# ioam3358 register map
Registers are 32-bit, access not given, no defined reset value unless marked. A register's access mark holds for its fields unless they carry their own. Addresses are absolute; registers are grouped by the start of their names; [hi:lo] are bit positions; {n}, {i} and the like mark numbered series.

## MMCHS2
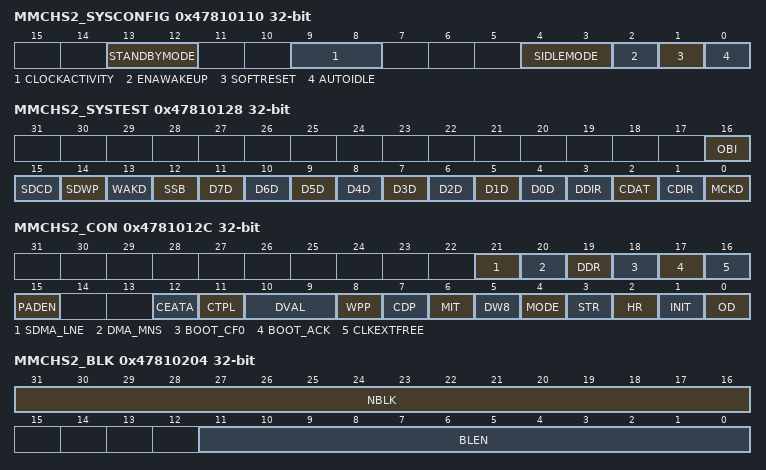
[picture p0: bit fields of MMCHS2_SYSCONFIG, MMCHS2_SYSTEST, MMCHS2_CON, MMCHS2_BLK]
0x47810110 MMCHS2_SYSCONFIG
  [13:12] STANDBYMODE, [9:8] CLOCKACTIVITY, [4:3] SIDLEMODE, [2] ENAWAKEUP, [1] SOFTRESET, [0] AUTOIDLE
0x47810114 MMCHS2_SYSSTATUS
  [0] RESETDONE
0x47810124 MMCHS2_CSRE
0x47810128 MMCHS2_SYSTEST
  [16] OBI, [15] SDCD, [14] SDWP, [13] WAKD, [12] SSB, [n+4] D{n}D (n=0..7), [3] DDIR, [2] CDAT, [1] CDIR, [0] MCKD
0x4781012C MMCHS2_CON
  [21] SDMA_LNE, [20] DMA_MNS, [19] DDR, [18] BOOT_CF0, [17] BOOT_ACK, [16] CLKEXTFREE, [15] PADEN, [12] CEATA, [11] CTPL, [10:9] DVAL, [8] WPP, [7] CDP, [6] MIT, [5] DW8, [4] MODE, [3] STR, [2] HR, [1] INIT, [0] OD
0x47810130 MMCHS2_PWCNT
  [15:0] PWRCNT
0x47810200 MMCHS2_SDMASA
0x47810204 MMCHS2_BLK
  [31:16] NBLK, [11:0] BLEN
0x47810208 MMCHS2_ARG
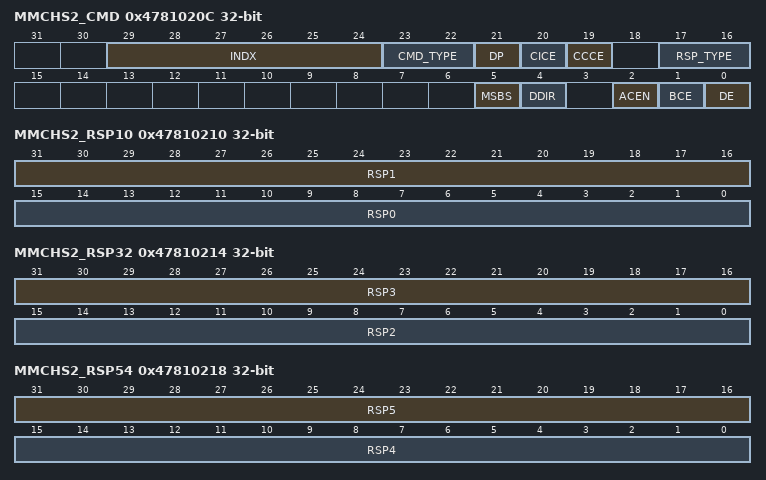
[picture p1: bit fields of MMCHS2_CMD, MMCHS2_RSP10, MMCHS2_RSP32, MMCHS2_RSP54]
0x4781020C MMCHS2_CMD
  [29:24] INDX, [23:22] CMD_TYPE, [21] DP, [20] CICE, [19] CCCE, [17:16] RSP_TYPE, [5] MSBS, [4] DDIR, [2] ACEN, [1] BCE, [0] DE
0x47810210 MMCHS2_RSP10
  [31:16] RSP1, [15:0] RSP0
0x47810214 MMCHS2_RSP32
  [31:16] RSP3, [15:0] RSP2
0x47810218 MMCHS2_RSP54
  [31:16] RSP5, [15:0] RSP4
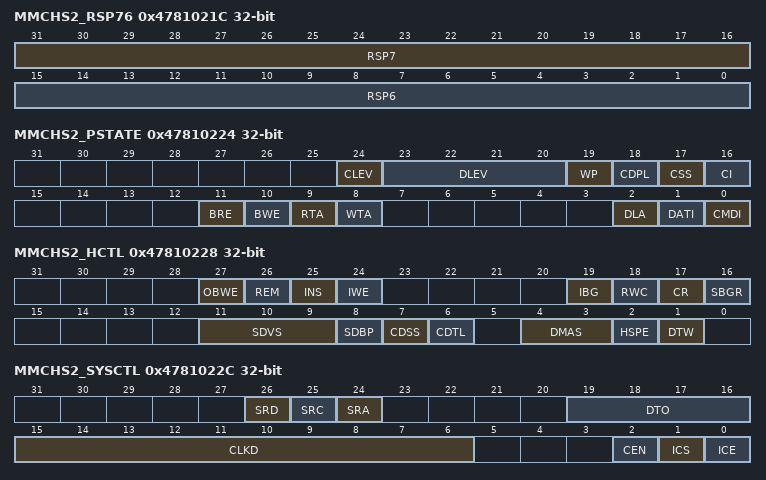
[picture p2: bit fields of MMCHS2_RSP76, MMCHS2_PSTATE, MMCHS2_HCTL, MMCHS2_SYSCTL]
0x4781021C MMCHS2_RSP76
  [31:16] RSP7, [15:0] RSP6
0x47810220 MMCHS2_DATA
0x47810224 MMCHS2_PSTATE
  [24] CLEV, [23:20] DLEV, [19] WP, [18] CDPL, [17] CSS, [16] CI, [11] BRE, [10] BWE, [9] RTA, [8] WTA, [2] DLA, [1] DATI, [0] CMDI
0x47810228 MMCHS2_HCTL
  [27] OBWE, [26] REM, [25] INS, [24] IWE, [19] IBG, [18] RWC, [17] CR, [16] SBGR, [11:9] SDVS, [8] SDBP, [7] CDSS, [6] CDTL, [4:3] DMAS, [2] HSPE, [1] DTW
0x4781022C MMCHS2_SYSCTL
  [26] SRD, [25] SRC, [24] SRA, [19:16] DTO, [15:6] CLKD, [2] CEN, [1] ICS, [0] ICE
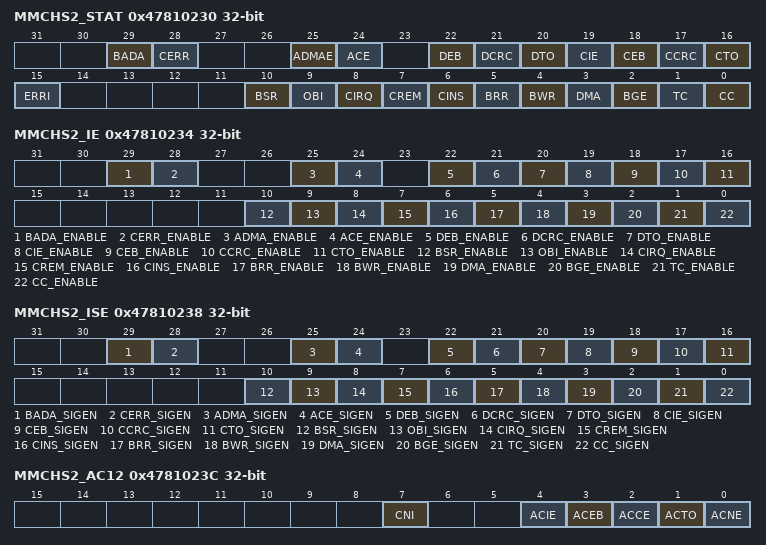
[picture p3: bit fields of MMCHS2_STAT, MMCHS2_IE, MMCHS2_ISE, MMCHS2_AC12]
0x47810230 MMCHS2_STAT
  [29] BADA, [28] CERR, [25] ADMAE, [24] ACE, [22] DEB, [21] DCRC, [20] DTO, [19] CIE, [18] CEB, [17] CCRC, [16] CTO, [15] ERRI, [10] BSR, [9] OBI, [8] CIRQ, [7] CREM, [6] CINS, [5] BRR, [4] BWR, [3] DMA, [2] BGE, [1] TC, [0] CC
0x47810234 MMCHS2_IE
  [29] BADA_ENABLE, [28] CERR_ENABLE, [25] ADMA_ENABLE, [24] ACE_ENABLE, [22] DEB_ENABLE, [21] DCRC_ENABLE, [20] DTO_ENABLE, [19] CIE_ENABLE, [18] CEB_ENABLE, [17] CCRC_ENABLE, [16] CTO_ENABLE, [10] BSR_ENABLE, [9] OBI_ENABLE, [8] CIRQ_ENABLE, [7] CREM_ENABLE, [6] CINS_ENABLE, [5] BRR_ENABLE, [4] BWR_ENABLE, [3] DMA_ENABLE, [2] BGE_ENABLE, [1] TC_ENABLE, [0] CC_ENABLE
0x47810238 MMCHS2_ISE
  [29] BADA_SIGEN, [28] CERR_SIGEN, [25] ADMA_SIGEN, [24] ACE_SIGEN, [22] DEB_SIGEN, [21] DCRC_SIGEN, [20] DTO_SIGEN, [19] CIE_SIGEN, [18] CEB_SIGEN, [17] CCRC_SIGEN, [16] CTO_SIGEN, [10] BSR_SIGEN, [9] OBI_SIGEN, [8] CIRQ_SIGEN, [7] CREM_SIGEN, [6] CINS_SIGEN, [5] BRR_SIGEN, [4] BWR_SIGEN, [3] DMA_SIGEN, [2] BGE_SIGEN, [1] TC_SIGEN, [0] CC_SIGEN
0x4781023C MMCHS2_AC12
  [7] CNI, [4] ACIE, [3] ACEB, [2] ACCE, [1] ACTO, [0] ACNE
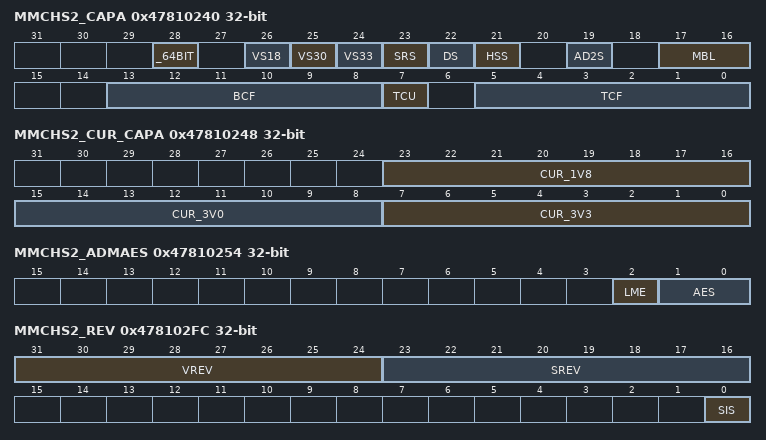
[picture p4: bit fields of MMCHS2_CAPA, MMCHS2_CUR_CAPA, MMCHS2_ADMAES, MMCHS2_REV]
0x47810240 MMCHS2_CAPA
  [28] _64BIT, [26] VS18, [25] VS30, [24] VS33, [23] SRS, [22] DS, [21] HSS, [19] AD2S, [17:16] MBL, [13:8] BCF, [7] TCU, [5:0] TCF
0x47810248 MMCHS2_CUR_CAPA
  [23:16] CUR_1V8, [15:8] CUR_3V0, [7:0] CUR_3V3
0x47810250 MMCHS2_FE
0x47810254 MMCHS2_ADMAES
  [2] LME, [1:0] AES
0x47810258 MMCHS2_ADMASAL
0x4781025C MMCHS2_ADMASAH
0x478102FC MMCHS2_REV
  [31:24] VREV, [23:16] SREV, [0] SIS

## UART0
0x44E09000 UART0_DLL 8-bit
0x44E09000 UART0_RHR 8-bit
0x44E09000 UART0_THR 8-bit
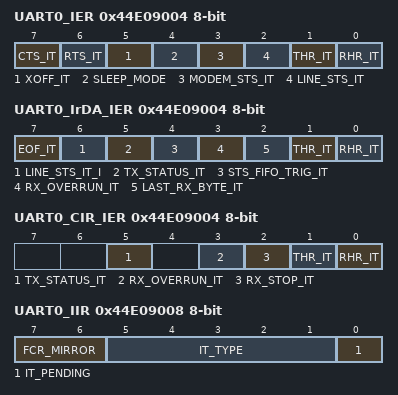
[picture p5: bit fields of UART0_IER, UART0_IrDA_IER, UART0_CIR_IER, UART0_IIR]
0x44E09004 UART0_IER 8-bit
  [7] CTS_IT, [6] RTS_IT, [5] XOFF_IT, [4] SLEEP_MODE, [3] MODEM_STS_IT, [2] LINE_STS_IT, [1] THR_IT, [0] RHR_IT
0x44E09004 UART0_DLH 8-bit
0x44E09004 UART0_IrDA_IER 8-bit
  [7] EOF_IT, [6] LINE_STS_IT_I, [5] TX_STATUS_IT, [4] STS_FIFO_TRIG_IT, [3] RX_OVERRUN_IT, [2] LAST_RX_BYTE_IT, [1] THR_IT, [0] RHR_IT
0x44E09004 UART0_CIR_IER 8-bit
  [5] TX_STATUS_IT, [3] RX_OVERRUN_IT, [2] RX_STOP_IT, [1] THR_IT, [0] RHR_IT
0x44E09008 UART0_IIR 8-bit
  [7:6] FCR_MIRROR, [5:1] IT_TYPE, [0] IT_PENDING
0x44E09008 UART0_FCR 8-bit
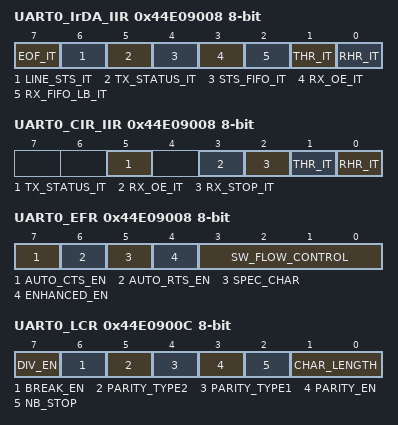
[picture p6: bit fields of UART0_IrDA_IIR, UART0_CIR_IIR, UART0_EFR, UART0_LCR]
0x44E09008 UART0_IrDA_IIR 8-bit
  [7] EOF_IT, [6] LINE_STS_IT, [5] TX_STATUS_IT, [4] STS_FIFO_IT, [3] RX_OE_IT, [2] RX_FIFO_LB_IT, [1] THR_IT, [0] RHR_IT
0x44E09008 UART0_CIR_IIR 8-bit
  [5] TX_STATUS_IT, [3] RX_OE_IT, [2] RX_STOP_IT, [1] THR_IT, [0] RHR_IT
0x44E09008 UART0_EFR 8-bit
  [7] AUTO_CTS_EN, [6] AUTO_RTS_EN, [5] SPEC_CHAR, [4] ENHANCED_EN, [3:0] SW_FLOW_CONTROL
0x44E0900C UART0_LCR 8-bit
  [7] DIV_EN, [6] BREAK_EN, [5] PARITY_TYPE2, [4] PARITY_TYPE1, [3] PARITY_EN, [2] NB_STOP, [1:0] CHAR_LENGTH
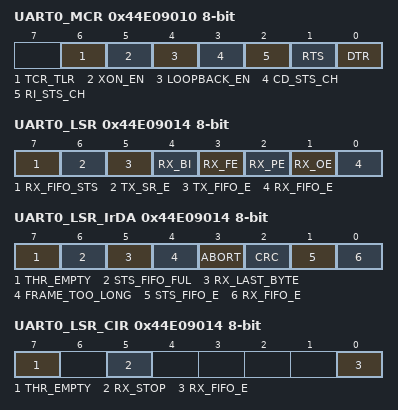
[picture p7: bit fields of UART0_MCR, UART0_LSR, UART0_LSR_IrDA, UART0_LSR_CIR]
0x44E09010 UART0_MCR 8-bit
  [6] TCR_TLR, [5] XON_EN, [4] LOOPBACK_EN, [3] CD_STS_CH, [2] RI_STS_CH, [1] RTS, [0] DTR
0x44E09010 UART0_XON1_ADDR1 8-bit
0x44E09014 UART0_LSR 8-bit
  [7] RX_FIFO_STS, [6] TX_SR_E, [5] TX_FIFO_E, [4] RX_BI, [3] RX_FE, [2] RX_PE, [1] RX_OE, [0] RX_FIFO_E
0x44E09014 UART0_XON2_ADDR2 8-bit
0x44E09014 UART0_LSR_IrDA 8-bit
  [7] THR_EMPTY, [6] STS_FIFO_FUL, [5] RX_LAST_BYTE, [4] FRAME_TOO_LONG, [3] ABORT, [2] CRC, [1] STS_FIFO_E, [0] RX_FIFO_E
0x44E09014 UART0_LSR_CIR 8-bit
  [7] THR_EMPTY, [5] RX_STOP, [0] RX_FIFO_E
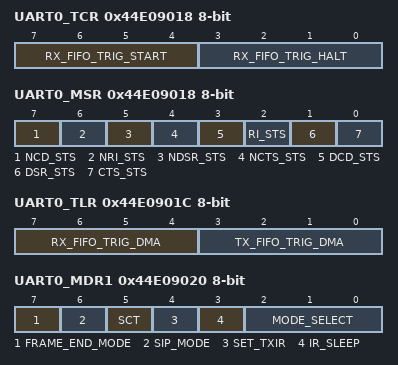
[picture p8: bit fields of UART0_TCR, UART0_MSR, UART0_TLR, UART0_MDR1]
0x44E09018 UART0_TCR 8-bit
  [7:4] RX_FIFO_TRIG_START, [3:0] RX_FIFO_TRIG_HALT
0x44E09018 UART0_XOFF1 8-bit
0x44E09018 UART0_MSR 8-bit
  [7] NCD_STS, [6] NRI_STS, [5] NDSR_STS, [4] NCTS_STS, [3] DCD_STS, [2] RI_STS, [1] DSR_STS, [0] CTS_STS
0x44E0901C UART0_TLR 8-bit
  [7:4] RX_FIFO_TRIG_DMA, [3:0] TX_FIFO_TRIG_DMA
0x44E0901C UART0_SPR 8-bit
0x44E0901C UART0_XOFF2 8-bit
0x44E09020 UART0_MDR1 8-bit
  [7] FRAME_END_MODE, [6] SIP_MODE, [5] SCT, [4] SET_TXIR, [3] IR_SLEEP, [2:0] MODE_SELECT
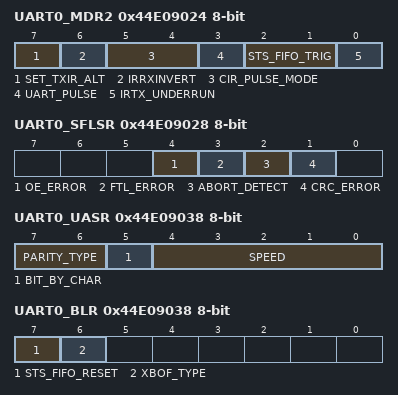
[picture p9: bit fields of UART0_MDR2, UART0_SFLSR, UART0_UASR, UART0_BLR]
0x44E09024 UART0_MDR2 8-bit
  [7] SET_TXIR_ALT, [6] IRRXINVERT, [5:4] CIR_PULSE_MODE, [3] UART_PULSE, [2:1] STS_FIFO_TRIG, [0] IRTX_UNDERRUN
0x44E09028 UART0_SFLSR 8-bit
  [4] OE_ERROR, [3] FTL_ERROR, [2] ABORT_DETECT, [1] CRC_ERROR
0x44E09028 UART0_TXFLL 8-bit
0x44E0902C UART0_TXFLH 8-bit
  [4:0] TXFLH
0x44E0902C UART0_RESUME 8-bit
0x44E09030 UART0_SFREGL 8-bit
0x44E09030 UART0_RXFLL 8-bit
0x44E09034 UART0_SFREGH 8-bit
  [3:0] SFREGH
0x44E09034 UART0_RXFLH 8-bit
  [3:0] RXFLH
0x44E09038 UART0_UASR 8-bit
  [7:6] PARITY_TYPE, [5] BIT_BY_CHAR, [4:0] SPEED
0x44E09038 UART0_BLR 8-bit
  [7] STS_FIFO_RESET, [6] XBOF_TYPE
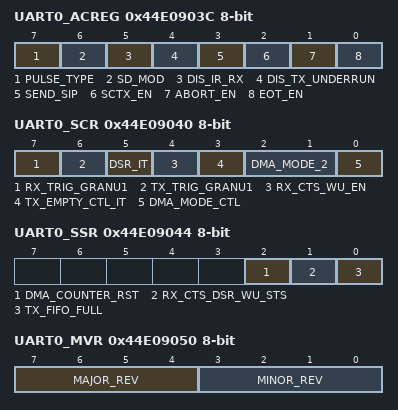
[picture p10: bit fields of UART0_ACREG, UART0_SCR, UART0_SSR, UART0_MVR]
0x44E0903C UART0_ACREG 8-bit
  [7] PULSE_TYPE, [6] SD_MOD, [5] DIS_IR_RX, [4] DIS_TX_UNDERRUN, [3] SEND_SIP, [2] SCTX_EN, [1] ABORT_EN, [0] EOT_EN
0x44E09040 UART0_SCR 8-bit
  [7] RX_TRIG_GRANU1, [6] TX_TRIG_GRANU1, [5] DSR_IT, [4] RX_CTS_WU_EN, [3] TX_EMPTY_CTL_IT, [2:1] DMA_MODE_2, [0] DMA_MODE_CTL
0x44E09044 UART0_SSR 8-bit
  [2] DMA_COUNTER_RST, [1] RX_CTS_DSR_WU_STS, [0] TX_FIFO_FULL
0x44E09048 UART0_EBLR 8-bit
0x44E09050 UART0_MVR 8-bit
  [7:4] MAJOR_REV, [3:0] MINOR_REV
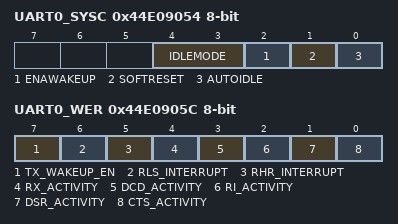
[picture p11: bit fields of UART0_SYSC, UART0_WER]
0x44E09054 UART0_SYSC 8-bit
  [4:3] IDLEMODE, [2] ENAWAKEUP, [1] SOFTRESET, [0] AUTOIDLE
0x44E09058 UART0_SYSS 8-bit
  [0] RESETDONE
0x44E0905C UART0_WER 8-bit
  [7] TX_WAKEUP_EN, [6] RLS_INTERRUPT, [5] RHR_INTERRUPT, [4] RX_ACTIVITY, [3] DCD_ACTIVITY, [2] RI_ACTIVITY, [1] DSR_ACTIVITY, [0] CTS_ACTIVITY
0x44E09060 UART0_CFPS 8-bit
